# EFR32MG24A020F1536IM40 register map
Vendor: Silicon Labs; Series: EFR32; File version: B
Registers are 32-bit, read-write, reset 0x0 unless marked. A register's access mark holds for its fields unless they carry their own. Offsets are from the block's base; [hi:lo] are bit positions; {n}, {i} and the like mark numbered series; 'fields as' and 'values as' point back to an identical list.

## PROTIMER_S — PROTIMER_S Registers
Base 0xA801C000
Same registers: PROTIMER_NS 0xB801C000
0x00 IPVERSION ro reset 0x2
0x04 EN
  [0] EN
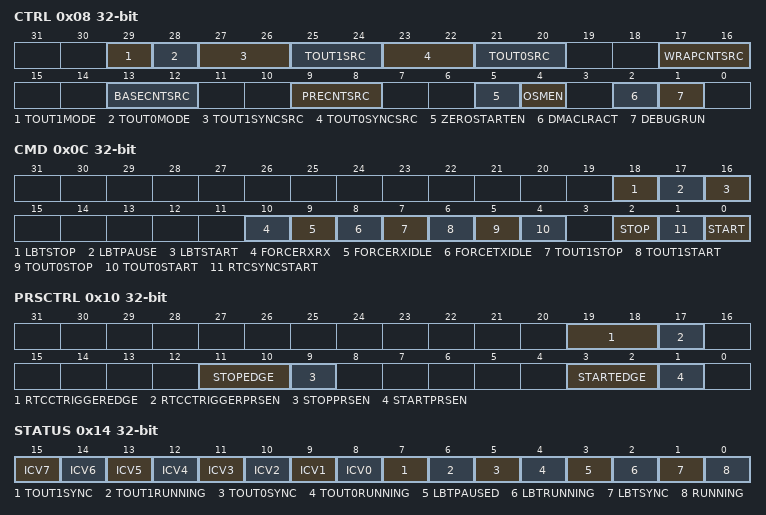
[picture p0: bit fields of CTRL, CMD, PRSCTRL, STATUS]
0x08 CTRL
  [29] TOUT1MODE — Repeat Mode
    0=FREE (When started, the TOUT1 counts down until it is stopped by software); 1=ONESHOT (TOUT1 is stopped after it reaches zero)
  [28] TOUT0MODE — Repeat Mode
    0=FREE (When started, the TOUT0 counts down until it is stopped by software); 1=ONESHOT (TOUT0 is stopped after it reaches zero)
  [27:26] TOUT1SYNCSRC — Select timeout counter 1 event
    0=DISABLED (No synchronization); 1=PRECNTOF (Pre-counter overflow event); 2=BASECNTOF (Base counter overflow event); 3=WRAPCNTOF (Wrap counter overflow event)
  [25:24] TOUT1SRC — Selects clock to timeout counter 1
    0=DISABLED (No counting); 1=PRECNTOF (Pre-counter overflow events); 2=BASECNTOF (Base counter overflow events); 3=WRAPCNTOF (Wrap counter overflow events)
  [23:22] TOUT0SYNCSRC — Select timeout counter 0 event
    values as TOUT1SYNCSRC
  [21:20] TOUT0SRC — Selects clock to timeout counter 0
    values as TOUT1SRC
  [17:16] WRAPCNTSRC — Selects clock to Wrap counter
    0=DISABLED (Disable Wrap counter); 1=PRECNTOF (Pre-counter overflow events); 2=BASECNTOF (Base counter overflow events); 3=UNUSED (Do not use)
  [13:12] BASECNTSRC — Selects clock to Base counter
    0=DISABLED (Disable base counter); 1=PRECNTOF (Pre-counter overflow events); 2=UNUSED0 (Do not use); 3=UNUSED1 (Do not use)
  [9:8] PRECNTSRC — Selects clock to Pre-counter
    0=DISABLED (Disable Pre-counter); 1=CLOCK (Module clock); 2=UNUSED0 (Do not use); 3=UNUSED1 (Do not use)
  [5] ZEROSTARTEN — Start from zero enable
    0=Protimer starts from the previous count value; 1=Protimer starts counting from zero
  [4] OSMEN — One-Shot Mode Enable
    0=Protimer continues to count when WRAP counter overflows; 1=Protimer stops counting when WRAP counter overflows
  [2] DMACLRACT — DMA Request Clear on Active
  [1] DEBUGRUN — Debug Mode Run Enable
    0=PROTIMER is frozen in debug mode; 1=PROTIMER is running in debug mode
0x0C CMD wo
  [18] LBTSTOP — LBT sequence stop
  [17] LBTPAUSE — Pause LBT sequence
  [16] LBTSTART — LBT sequence start
  [10] FORCERXRX — Force to Rx state of rx_state
  [9] FORCERXIDLE — Force to Idle state of rx_state
  [8] FORCETXIDLE — Force to Idle state of tx_state
  [7] TOUT1STOP — Stop Timeout counter 0
  [6] TOUT1START — Start Timeout counter 1
  [5] TOUT0STOP — Stop Timeout counter 0
  [4] TOUT0START — Start Timeout counter 0
  [2] STOP — Stop PROTIMER
  [1] RTCSYNCSTART — Start PROTIMER Synchronized with RTCC
  [0] START — Start PROTIMER
0x10 PRSCTRL
  [19:18] RTCCTRIGGEREDGE — RTCC Trigger Edge Select
    0=RISING (Rising edges detected); 1=FALLING (Falling edges detected); 2=BOTH (Both edges detected); 3=DISABLED (No edge detection, signal is left as it is)
  [17] RTCCTRIGGERPRSEN — Enable RTCC Trigger from PRS.
  [11:10] STOPEDGE — Stop Command Edge Select
    values as RTCCTRIGGEREDGE
  [9] STOPPRSEN — Enable Protimer stop commands from PRS.
  [3:2] STARTEDGE — Start Command Edge Select
    values as RTCCTRIGGEREDGE
  [1] STARTPRSEN — Enable Protimer start commands from PRS.
0x14 STATUS ro
  [15] ICV7 — CC7 Capture Valid
  [14] ICV6 — CC6 Capture Valid
  [13] ICV5 — CC5 Capture Valid
  [n+8] ICV{n} (n=0..4) — CC{n} Capture Valid
    0=PROTIMER_CC{n}_PRE, -BASE or -WRAP does not contain a valid capture value; 1=PROTIMER_CC{n}_PRE, -BASE or -WRAP contains a valid and unread capture value
  [7] TOUT1SYNC — Timeout Counter 1 Synchronizing
  [6] TOUT1RUNNING — Timeout Counter 1 Running
  [5] TOUT0SYNC — Timeout Counter 0 Synchronizing
  [4] TOUT0RUNNING — Timeout Counter 0 Running
  [3] LBTPAUSED — LBT has been paused.
  [2] LBTRUNNING
  [1] LBTSYNC — LBT Synchronizing
  [0] RUNNING
0x18 PRECNT
  [15:0] PRECNT — Pre Counter Value
0x1C BASECNT
  [15:0] BASECNT — Base Counter Value
0x20 WRAPCNT
  [31:0] WRAPCNT — Wrap Counter Value
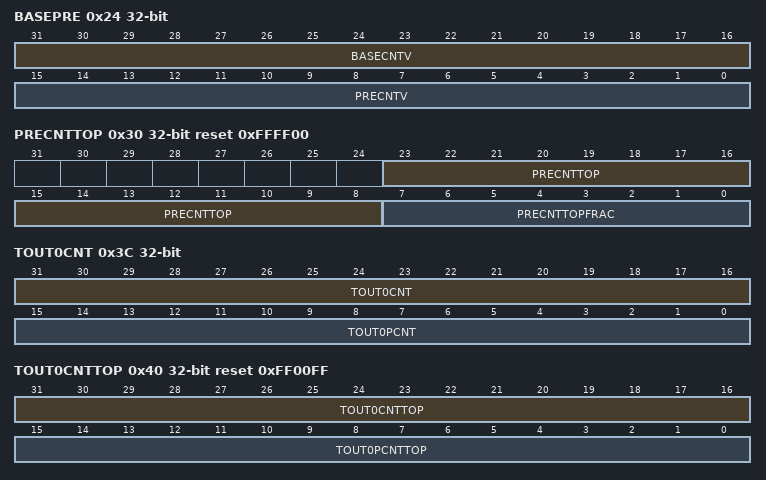
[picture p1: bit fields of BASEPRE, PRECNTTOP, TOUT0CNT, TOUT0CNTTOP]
0x24 BASEPRE ro
  [31:16] BASECNTV — Base counter value
  [15:0] PRECNTV — Pre counter value
0x28 LWRAPCNT ro
  [31:0] LWRAPCNT — Latched Wrap Counter Value
0x2C PRECNTTOPADJ
  [15:0] PRECNTTOPADJ — PRECNT Top Adjust Value
0x30 PRECNTTOP reset 0xFFFF00
  [23:8] PRECNTTOP — PRECNT Top Value
  [7:0] PRECNTTOPFRAC — PRECNT Top Fractional Value
0x34 BASECNTTOP reset 0xFFFF
  [15:0] BASECNTTOP — BASECNT Top Value
0x38 WRAPCNTTOP reset 0xFFFFFFFF
  [31:0] WRAPCNTTOP — WRAPCNT Top Value
0x3C TOUT0CNT
  [31:16] TOUT0CNT — TOUT0CNT Value
  [15:0] TOUT0PCNT — TOUT0PCNT Value
0x40 TOUT0CNTTOP reset 0xFF00FF
  [31:16] TOUT0CNTTOP — TOUT0CNTTOP Value
  [15:0] TOUT0PCNTTOP — TOUT0PCNTTOP Value
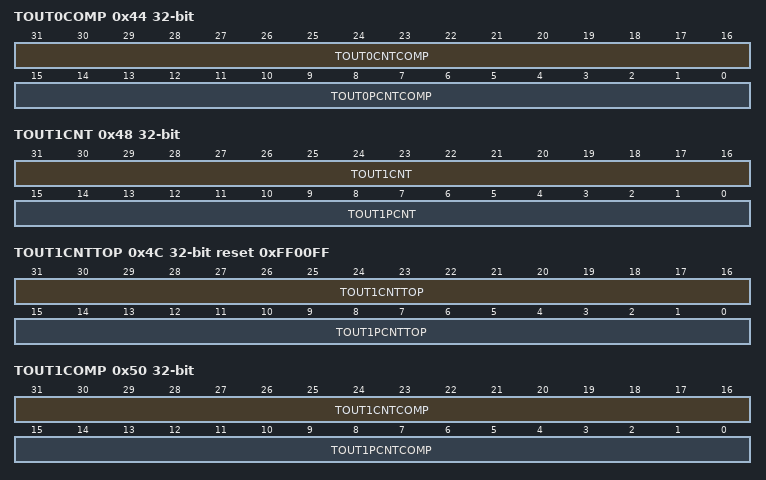
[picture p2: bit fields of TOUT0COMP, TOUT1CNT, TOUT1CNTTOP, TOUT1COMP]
0x44 TOUT0COMP
  [31:16] TOUT0CNTCOMP — TOUT0CNTCOMP Value
  [15:0] TOUT0PCNTCOMP
0x48 TOUT1CNT
  [31:16] TOUT1CNT — TOUT1CNT Value
  [15:0] TOUT1PCNT — TOUT1PCNT Value
0x4C TOUT1CNTTOP reset 0xFF00FF
  [31:16] TOUT1CNTTOP — TOUT1CNTTOP Value
  [15:0] TOUT1PCNTTOP — TOUT1PCNTTOP Value
0x50 TOUT1COMP
  [31:16] TOUT1CNTCOMP — TOUT1CNTCOMP Value
  [15:0] TOUT1PCNTCOMP
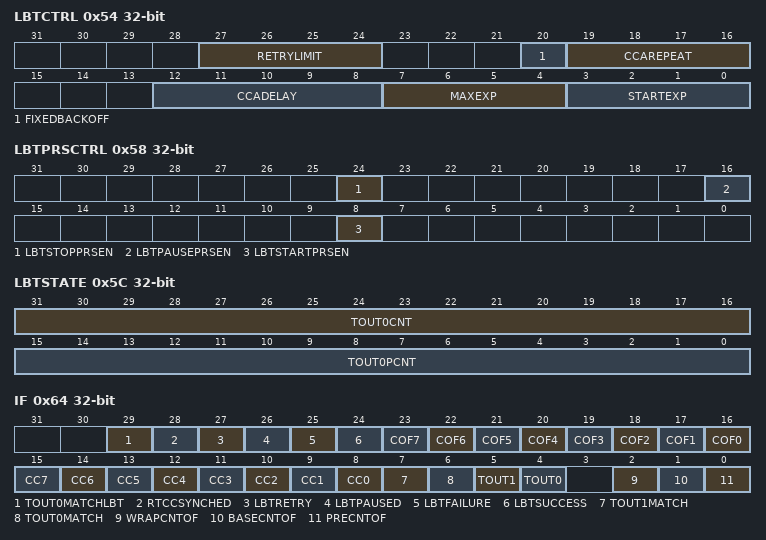
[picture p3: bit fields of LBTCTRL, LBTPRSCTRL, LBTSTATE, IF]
0x54 LBTCTRL
  [27:24] RETRYLIMIT
  [20] FIXEDBACKOFF
  [19:16] CCAREPEAT — Clear Channel Assessment Repeat
  [12:8] CCADELAY — Clear Channel Assessment Delay
  [7:4] MAXEXP — Maximum Exponent
    {v}=EXP{v} (MAXEXP value = {v}) (v=0..8)
  [3:0] STARTEXP — Start Exponent
    0=EXP0 (STARTEXP value = 0 (used for Fast TX)); {v}=EXP{v} (STARTEXP value = {v}) (v=1..8)
0x58 LBTPRSCTRL
  [24] LBTSTOPPRSEN — Enable LBT stop commands from PRS.
  [16] LBTPAUSEPRSEN — Enable LBT pause commands from PRS.
  [8] LBTSTARTPRSEN — Enable LBT start commands from PRS.
0x5C LBTSTATE
  [31:16] TOUT0CNT — TOUT0CNT value to be saved
  [15:0] TOUT0PCNT — TOUT0PCNT value to be saved
0x60 RANDOM
  [15:0] RANDOM — Pseudo Random Value
0x64 IF
  [29] TOUT0MATCHLBT — TOUT0 compare match interrupt flag
  [28] RTCCSYNCHED — PROTIMER synchronized with the RTCC
  [27] LBTRETRY — Listen Before Talk Retry
  [26] LBTPAUSED — Listen Before Talk Paused
  [25] LBTFAILURE — Listen Before Talk Failure
  [24] LBTSUCCESS — Listen Before Talk Success
  [n+16] COF{n} (n=0..7) — CC Channel {n} Overflow Interrupt Flag
  [n+8] CC{n} (n=0..7) — CC Channel {n} Interrupt Flag
  [7] TOUT1MATCH — TOUT1 compare match interrupt flag
  [6] TOUT0MATCH — TOUT0 compare match interrupt flag
  [5] TOUT1 — TOUT1 underflow interrupt flag
  [4] TOUT0 — TOUT0 underflow interrupt flag
  [2] WRAPCNTOF — WRAPCNT Overflow Interrupt Flag
  [1] BASECNTOF — BASECNT Overflow Interrupt Flag
  [0] PRECNTOF — PRECNT Overflow Interrupt Flag
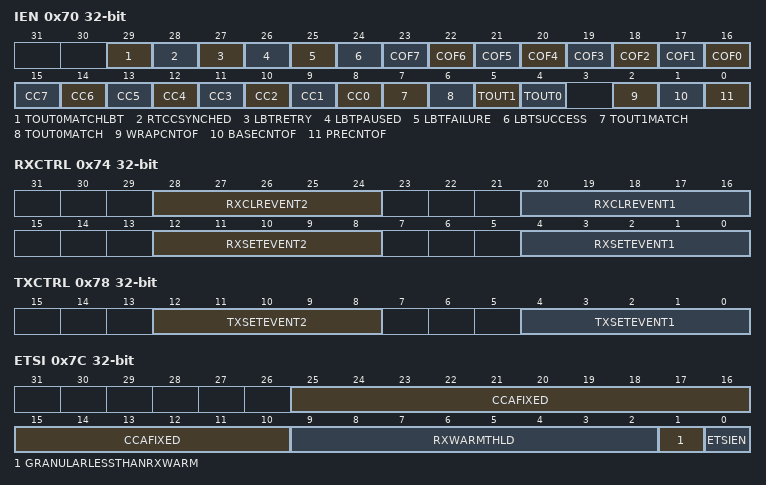
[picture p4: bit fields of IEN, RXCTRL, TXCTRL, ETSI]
0x70 IEN
  [29] TOUT0MATCHLBT — TOUT0MATCHLBT Interrupt Enable
  [28] RTCCSYNCHED — RTCCSYNCHED Interrupt Enable
  [27] LBTRETRY — LBTRETRY Interrupt Enable
  [26] LBTPAUSED — LBTPAUSED Interrupt Enable
  [25] LBTFAILURE — LBTFAILURE Interrupt Enable
  [24] LBTSUCCESS — LBTSUCCESS Interrupt Enable
  [n+16] COF{n} (n=0..7) — COF{n} Interrupt Enable
  [n+8] CC{n} (n=0..7) — CC{n} Interrupt Enable
  [7] TOUT1MATCH — TOUT1MATCH Interrupt Enable
  [6] TOUT0MATCH — TOUT0MATCH Interrupt Enable
  [5] TOUT1 — TOUT1 Interrupt Enable
  [4] TOUT0 — TOUT0 Interrupt Enable
  [2] WRAPCNTOF — WRAPCNTOF Interrupt Enable
  [1] BASECNTOF — BASECNTOF Interrupt Enable
  [0] PRECNTOF — PRECNTOF Interrupt Enable
0x74 RXCTRL
  [28:24] RXCLREVENT2 — Second event that clears RX req signal
  [20:16] RXCLREVENT1 — First event that clears RX req signal
  [12:8] RXSETEVENT2 — Second event that sets RX req signal
  [4:0] RXSETEVENT1 — First event that sets RX req signal
    0=DISABLED (Request is never set); 1=ALWAYS (Does not wait for any particular event); 2=PRECNTOF (Pre counter overflow); 3=BASECNTOF (Base counter overflow); 4=WRAPCNTOF (Wrap counter overflow); 5=TOUT0UF (Timeout counter 0 underflow); 6=TOUT1UF (Timeout counter 1 underflow); 7=TOUT0MATCH (Timeout counter 0 match); 8=TOUT1MATCH (Timeout counter 1 match); {v}=CC{v-9} (Channel {v-9} Capture/Compare event) (v=9..13); 14=TXDONE (MOD indicated that TX completed); 15=RXDONE (FRC indicated that RX completed); 16=TXORRXDONE (MOD/FRC indicated that TX or RX completed); 17=FDET0 (DEMOD indicated that syncword 0 was detected); 18=FDET1 (DEMOD indicated that syncword 1 was detected); 19=FDET0OR1 (DEMOD indicated that syncword 0 or 1 was detected); 20=LBTSUCCESS (LBT completed successfully); 21=LBTRETRY (LBT detected occupied channel and will try again); 22=LBTFAILURE (LBT could not start transmission); 23=ANYLBT (Any LBT event); 24=CCAACK (A CCA measurement completed); 25=CCA (A CCA measurement completed, and channel was clear); 26=NOTCCA (A CCA measurement completed, and channel was busy); 27=TOUT0MATCHLBT (Timeout counter 0 match occurred during LBT operation)
0x78 TXCTRL
  [12:8] TXSETEVENT2 — Second event that sets TX req signal
  [4:0] TXSETEVENT1 — First event that sets TX req signal
    values as RXCTRL.RXSETEVENT1
0x7C ETSI
  [25:10] CCAFIXED — Fixed listening time
  [9:2] RXWARMTHLD — Minimum backoff period for RXWARM
  [1] GRANULARLESSTHANRXWARM
  [0] ETSIEN — ETSI LBT enabling
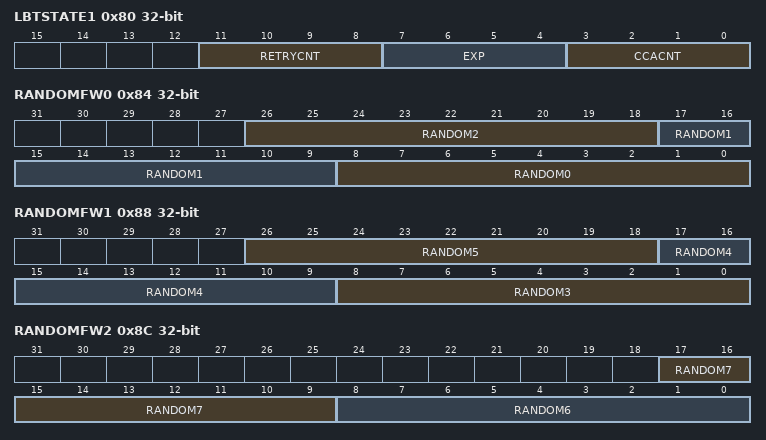
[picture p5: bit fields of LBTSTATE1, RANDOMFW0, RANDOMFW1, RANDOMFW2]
0x80 LBTSTATE1
  [11:8] RETRYCNT — LBT Retry counter
  [7:4] EXP — LBT Exponent
  [3:0] CCACNT — Current CCA counter value
0x84 RANDOMFW0
  [26:18] RANDOM2 — Linear random backoff period from FW
  [17:9] RANDOM1 — Linear random backoff period from FW
  [8:0] RANDOM0 — Linear random backoff period from FW
0x88 RANDOMFW1
  [26:18] RANDOM5 — Linear random backoff period from FW
  [17:9] RANDOM4 — Linear random backoff period from FW
  [8:0] RANDOM3 — Linear random backoff period from FW
0x8C RANDOMFW2
  [17:9] RANDOM7 — Linear random backoff period from FW
  [8:0] RANDOM6 — Linear random backoff period from FW
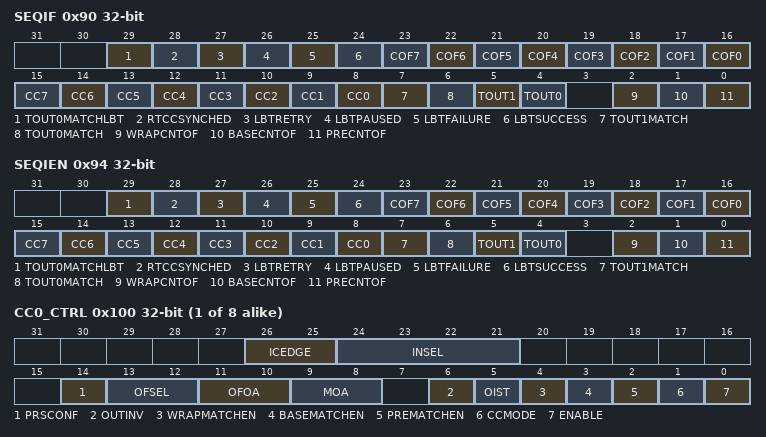
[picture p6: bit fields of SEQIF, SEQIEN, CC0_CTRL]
0x90 SEQIF
  fields as IF
0x94 SEQIEN
  fields as IEN
{0x100+0x10*i} CC{i}_CTRL (i=0..7)
  [26:25] ICEDGE — Input Capture Edge Select
    values as PRSCTRL.RTCCTRIGGEREDGE
  [24:21] INSEL — Capture input selection
    0=PRS (Use the selected PRS channel); 1=TXDONE (TX completed); 2=RXDONE (RX completed); 3=TXORRXDONE (TX or RX completed); 4=FRAMEDET0 (Demodulator found sync word 0); 5=FRAMEDET1 (Demodulator found sync word 1); 6=FDET0OR1 (Demodulator found sync word 0 or 1); 7=MODSYNCSENT (Modulator sync word sent); 8=RXEOF (RX at end of frame from demodulator); 9=PRORTC0 (PRORTC capture/compare 0); 10=PRORTC1 (PRORTC capture/compare 1)
  [14] PRSCONF — PRS Configuration
    0=PULSE (Each CC event will generate a one HFRADIOCLK cycle high pulse); 1=LEVEL (Should be used when OFSEL, OFOA or MOA are specified.)
  [13:12] OFSEL — Select counter for OFOA bits
    0=PRECNT (Use PRECNT overflow); 1=BASECNT (Use BASECNT overflow); 2=WRAPCNT (Use WRAPCNT overflow); 3=DISABLED
  [11:10] OFOA — Overflow Output Action
    0=DISABLED (No action); 1=TOGGLE (Toggle output when the selected counter has an overflow event.); 2=CLEAR (Clear output when the selected counter has an overflow event.); 3=SET (Set output when the selected counter has an overflow event.)
  [9:8] MOA — Match Output Action
    0=DISABLED (No action on compare match); 1=TOGGLE (Toggle output on compare match in COMPARE mode.); 2=CLEAR (Clear output on compare match in COMPARE mode.); 3=SET (Set output on compare match in COMPARE mode.)
  [6] OUTINV — Output Invert
  [5] OIST — Output Initial State
  [4] WRAPMATCHEN — Enable WRAPCNT matching
  [3] BASEMATCHEN — Enable BASECNT matching
  [2] PREMATCHEN — Enable PRECNT matching
  [1] CCMODE — Compare/Capture mode
    0=COMPARE (Compare mode selected); 1=CAPTURE (Capture mode selected)
  [0] ENABLE — Channel Enable
{0x104+0x10*i} CC{i}_PRE (i=0..7)
  [15:0] PRE — CC Channel PRE Value
{0x108+0x10*i} CC{i}_BASE (i=0..7)
  [15:0] BASE — CC Channel BASE Value
{0x10C+0x10*i} CC{i}_WRAP (i=0..7)
  [31:0] WRAP — CC Channel WRAP Value
